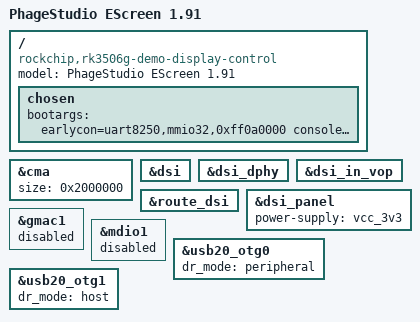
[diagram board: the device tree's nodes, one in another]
// SPDX-License-Identifier: (GPL-2.0+ OR MIT)
/*
 * Copyright (c) 2024 Rockchip Electronics Co., Ltd.
 */

/dts-v1/;

#include "rk3506-pgs-escreen-191.dtsi"

/ {
	model = "PhageStudio EScreen 1.91";
	compatible = "rockchip,rk3506g-demo-display-control", "rockchip,rk3506";

	chosen {
		bootargs = "earlycon=uart8250,mmio32,0xff0a0000 console=tty1 console=ttyFIQ0 root=/dev/mmcblk0p3 rootfstype=ext4 rootwait snd_aloop.index=7 snd_aloop.use_raw_jiffies=1";
	};
};

/**********display**********/
&cma {
	size = <0x2000000>;
};

&dsi {
	status = "okay";
};

&dsi_dphy {
	status = "okay";
};

&dsi_in_vop {
	status = "okay";
};

&route_dsi {
	status = "okay";
};

&dsi_panel {
	power-supply = <&vcc_3v3>;
};

/**********ethernet**********/
&gmac1 {
	status = "disabled";
};

&mdio1 {
	status = "disabled";
};

/**********usb**********/
&usb20_otg0 {
	dr_mode = "peripheral";
	status = "okay";
};

&usb20_otg1 {
	dr_mode = "host";
	status = "okay";
};
